# ATSAMR21E19A register map
Vendor: Atmel Corporation; File version: D
CPU: CM0+ r0p1, little endian, no MPU, no FPU, 0x2 interrupt priority bits, 0x0 interrupts
Registers are 32-bit, read-write, reset 0x0 unless marked. A register's access mark holds for its fields unless they carry their own. Offsets are from the block's base; [hi:lo] are bit positions; {n}, {i} and the like mark numbered series; 'fields as' and 'values as' point back to an identical list.

## PAC0 — Peripheral Access Controller 0
Base 0x40000000; register names take the prefix PAC_
0x00 WPCLR — Write Protection Clear
  [31:1] WP
0x04 WPSET — Write Protection Set
  [31:1] WP

## PAC1 — Peripheral Access Controller 1
Base 0x41000000; register names take the prefix PAC_
Registers as PAC0.

## PAC2 — Peripheral Access Controller 2
Base 0x42000000; register names take the prefix PAC_
Registers as PAC0.

## PM — Power Manager
Base 0x40000400; register names take the prefix PM_
0x00 CTRL 8-bit — Control
0x01 SLEEP 8-bit — Sleep Mode
  [1:0] IDLE — Idle Mode Configuration
    0=CPU (The CPU clock domain is stopped); 1=AHB (The CPU and AHB clock domains are stopped); 2=APB (The CPU, AHB and APB clock domains are stopped)
0x08 CPUSEL 8-bit — CPU Clock Select
  [2:0] CPUDIV — CPU Prescaler Selection
    0=DIV1 (Divide by 1); 1=DIV2 (Divide by 2); 2=DIV4 (Divide by 4); 3=DIV8 (Divide by 8); 4=DIV16 (Divide by 16); 5=DIV32 (Divide by 32); 6=DIV64 (Divide by 64); 7=DIV128 (Divide by 128)
0x09 APBASEL 8-bit — APBA Clock Select
  [2:0] APBADIV — APBA Prescaler Selection
    values as CPUSEL.CPUDIV
0x0A APBBSEL 8-bit — APBB Clock Select
  [2:0] APBBDIV — APBB Prescaler Selection
    values as CPUSEL.CPUDIV
0x0B APBCSEL 8-bit — APBC Clock Select
  [2:0] APBCDIV — APBC Prescaler Selection
    values as CPUSEL.CPUDIV
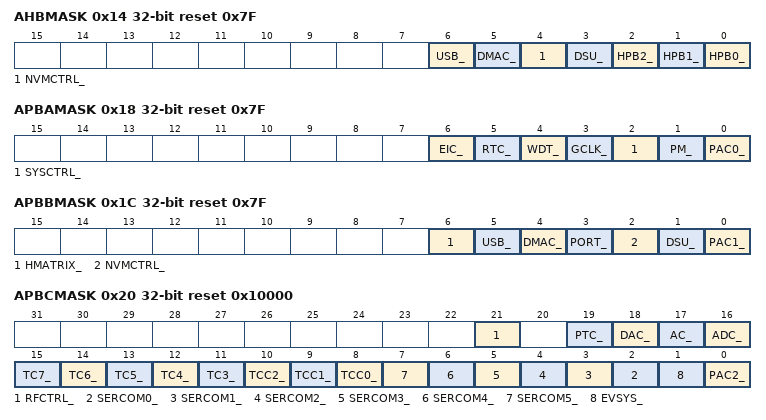
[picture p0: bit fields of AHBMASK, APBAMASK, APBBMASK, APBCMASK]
0x14 AHBMASK reset 0x7F
  [6] USB_ — USB AHB Clock Mask
  [5] DMAC_ — DMAC AHB Clock Mask
  [4] NVMCTRL_ — NVMCTRL AHB Clock Mask
  [3] DSU_ — DSU AHB Clock Mask
  [2] HPB2_ — HPB2 AHB Clock Mask
  [1] HPB1_ — HPB1 AHB Clock Mask
  [0] HPB0_ — HPB0 AHB Clock Mask
0x18 APBAMASK reset 0x7F
  [6] EIC_ — EIC APB Clock Enable
  [5] RTC_ — RTC APB Clock Enable
  [4] WDT_ — WDT APB Clock Enable
  [3] GCLK_ — GCLK APB Clock Enable
  [2] SYSCTRL_ — SYSCTRL APB Clock Enable
  [1] PM_ — PM APB Clock Enable
  [0] PAC0_ — PAC0 APB Clock Enable
0x1C APBBMASK reset 0x7F
  [6] HMATRIX_ — HMATRIX APB Clock Enable
  [5] USB_ — USB APB Clock Enable
  [4] DMAC_ — DMAC APB Clock Enable
  [3] PORT_ — PORT APB Clock Enable
  [2] NVMCTRL_ — NVMCTRL APB Clock Enable
  [1] DSU_ — DSU APB Clock Enable
  [0] PAC1_ — PAC1 APB Clock Enable
0x20 APBCMASK reset 0x10000
  [21] RFCTRL_ — RFCTRL APB Clock Enable
  [19] PTC_ — PTC APB Clock Enable
  [18] DAC_ — DAC APB Clock Enable
  [17] AC_ — AC APB Clock Enable
  [16] ADC_ — ADC APB Clock Enable
  [n+8] TC{n}_ (n=3..7) — TC{n} APB Clock Enable
  [10] TCC2_ — TCC2 APB Clock Enable
  [9] TCC1_ — TCC1 APB Clock Enable
  [8] TCC0_ — TCC0 APB Clock Enable
  [n+2] SERCOM{n}_ (n=0..5) — SERCOM{n} APB Clock Enable
  [1] EVSYS_ — EVSYS APB Clock Enable
  [0] PAC2_ — PAC2 APB Clock Enable
0x34 INTENCLR 8-bit — Interrupt Enable Clear
  [0] CKRDY — Clock Ready Interrupt Enable
0x35 INTENSET 8-bit — Interrupt Enable Set
  [0] CKRDY — Clock Ready Interrupt Enable
0x36 INTFLAG 8-bit — Interrupt Flag Status and Clear
  [0] CKRDY — Clock Ready
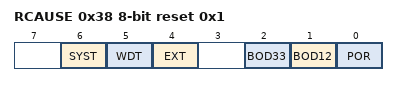
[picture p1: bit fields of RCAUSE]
0x38 RCAUSE 8-bit ro reset 0x1 — Reset Cause
  [6] SYST — System Reset Request
  [5] WDT — Watchdog Reset
  [4] EXT — External Reset
  [2] BOD33 — Brown Out 33 Detector Reset
  [1] BOD12 — Brown Out 12 Detector Reset
  [0] POR — Power On Reset

## PORT — Port Module
Base 0x41004400; register names take the prefix PORT_
{0x0+0x80*i} DIR{i} (i=0..2) — Data Direction
  [31:0] DIR — Port Data Direction
{0x4+0x80*i} DIRCLR{i} (i=0..2) — Data Direction Clear
  [31:0] DIRCLR — Port Data Direction Clear
{0x8+0x80*i} DIRSET{i} (i=0..2) — Data Direction Set
  [31:0] DIRSET — Port Data Direction Set
{0xC+0x80*i} DIRTGL{i} (i=0..2) — Data Direction Toggle
  [31:0] DIRTGL — Port Data Direction Toggle
{0x10+0x80*i} OUT{i} (i=0..2) — Data Output Value
  [31:0] OUT — Port Data Output Value
{0x14+0x80*i} OUTCLR{i} (i=0..2) — Data Output Value Clear
  [31:0] OUTCLR — Port Data Output Value Clear
{0x18+0x80*i} OUTSET{i} (i=0..2) — Data Output Value Set
  [31:0] OUTSET — Port Data Output Value Set
{0x1C+0x80*i} OUTTGL{i} (i=0..2) — Data Output Value Toggle
  [31:0] OUTTGL — Port Data Output Value Toggle
{0x20+0x80*i} IN{i} ro (i=0..2) — Data Input Value
  [31:0] IN — Port Data Input Value
{0x24+0x80*i} CTRL{i} (i=0..2) — Control
  [31:0] SAMPLING wo — Input Sampling Mode
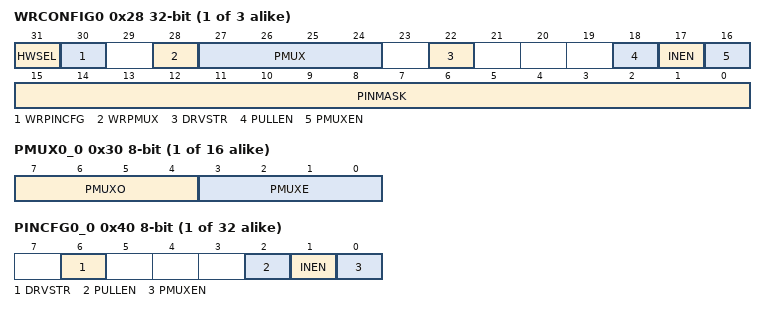
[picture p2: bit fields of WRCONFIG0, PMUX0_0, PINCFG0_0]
{0x28+0x80*i} WRCONFIG{i} wo (i=0..2) — Write Configuration
  [31] HWSEL — Half-Word Select
  [30] WRPINCFG — Write PINCFG
  [28] WRPMUX — Write PMUX
  [27:24] PMUX — Peripheral Multiplexing
  [22] DRVSTR — Output Driver Strength Selection
  [18] PULLEN — Pull Enable
  [17] INEN — Input Enable
  [16] PMUXEN — Peripheral Multiplexer Enable
  [15:0] PINMASK — Pin Mask for Multiple Pin Configuration
{0x30+i} PMUX0_{i} 8-bit (i=0..15) — Peripheral Multiplexing n - Group 0
  [7:4] PMUXO — Peripheral Multiplexing Odd
    0=A (Peripheral function A selected); 1=B (Peripheral function B selected); 2=C (Peripheral function C selected); 3=D (Peripheral function D selected); 4=E (Peripheral function E selected); 5=F (Peripheral function F selected); 6=G (Peripheral function G selected); 7=H (Peripheral function H selected)
  [3:0] PMUXE — Peripheral Multiplexing Even
    values as PMUXO
{0x40+i} PINCFG0_{i} 8-bit (i=0..31) — Pin Configuration n - Group 0
  [6] DRVSTR wo — Output Driver Strength Selection
  [2] PULLEN — Pull Enable
  [1] INEN — Input Enable
  [0] PMUXEN — Peripheral Multiplexer Enable
{0xB0+i} PMUX1_{i} (i=0..15) — Peripheral Multiplexing n - Group 1
{0xC0+i} PINCFG1_{i} (i=0..31) — Pin Configuration n - Group 1
{0x130+i} PMUX2_{i} (i=0..15) — Peripheral Multiplexing n - Group 2
{0x140+i} PINCFG2_{i} (i=0..31) — Pin Configuration n - Group 2

## RFCTRL — RF233 control module
Base 0x42005400; register names take the prefix RFCTRL_
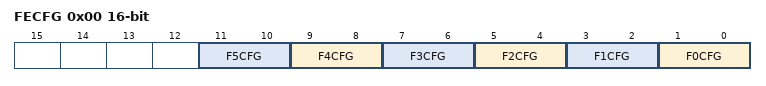
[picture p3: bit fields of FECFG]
0x00 FECFG 16-bit — Front-end control bus configuration
  [2n+1:2n] F{n}CFG (n=0..5) — Front-end control signal {n} configuration

## RTC — Real-Time Counter
Base 0x40001400; register names take the prefix RTC_

## SERCOM0 — Serial Communication Interface 0
Base 0x42000800; register names take the prefix SERCOM_

## SERCOM1 — Serial Communication Interface 1
Base 0x42000C00; register names take the prefix SERCOM_

## SERCOM2 — Serial Communication Interface 2
Base 0x42001000; register names take the prefix SERCOM_

## SERCOM3 — Serial Communication Interface 3
Base 0x42001400; register names take the prefix SERCOM_

## SERCOM4 — Serial Communication Interface 4
Base 0x42001800; register names take the prefix SERCOM_

## SERCOM5 — Serial Communication Interface 5
Base 0x42001C00; register names take the prefix SERCOM_

## TC3 — Basic Timer Counter 3
Base 0x42002C00; register names take the prefix TC_

## TC4 — Basic Timer Counter 4
Base 0x42003000; register names take the prefix TC_

## TC5 — Basic Timer Counter 5
Base 0x42003400; register names take the prefix TC_

## TC6 — Basic Timer Counter 6
Base 0x42003800; register names take the prefix TC_

## TC7 — Basic Timer Counter 7
Base 0x42003C00; register names take the prefix TC_

## USB — Universal Serial Bus
Base 0x41005000; register names take the prefix USB_

## WDT — Watchdog Timer
Base 0x40001000; register names take the prefix WDT_
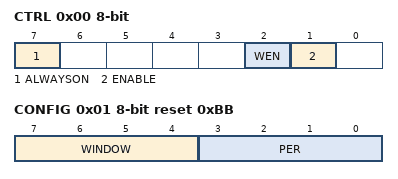
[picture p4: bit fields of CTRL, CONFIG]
0x00 CTRL 8-bit — Control
  [7] ALWAYSON
  [2] WEN — Watchdog Timer Window Mode Enable
  [1] ENABLE
0x01 CONFIG 8-bit reset 0xBB — Configuration
  [7:4] WINDOW — Window Mode Time-Out Period
    0=8 clock cycles; 1=16 clock cycles; 2=32 clock cycles; 3=64 clock cycles; 4=128 clock cycles; 5=256 clock cycles; 6=512 clock cycles; 7=1K (1024 clock cycles); 8=2K (2048 clock cycles); 9=4K (4096 clock cycles); 10=8K (8192 clock cycles); 11=16K (16384 clock cycles)
  [3:0] PER — Time-Out Period
    values as WINDOW
0x02 EWCTRL 8-bit reset 0xB — Early Warning Interrupt Control
  [3:0] EWOFFSET — Early Warning Interrupt Time Offset
    values as CONFIG.WINDOW
0x04 INTENCLR 8-bit — Interrupt Enable Clear
  [0] EW — Early Warning Interrupt Enable
0x05 INTENSET 8-bit — Interrupt Enable Set
  [0] EW — Early Warning Interrupt Enable
0x06 INTFLAG 8-bit — Interrupt Flag Status and Clear
  [0] EW — Early Warning
0x07 STATUS 8-bit ro
  [7] SYNCBUSY — Synchronization Busy
0x08 CLEAR 8-bit wo
  [7:0] CLEAR — Watchdog Clear
    165=KEY (Clear Key)
